# STM32WB10_CM4 register map
File version: 1.5
CPU: CM4 r0p1, little endian, MPU, FPU, 4 interrupt priority bits
Registers are 32-bit, read-write, reset 0x0 unless marked. A register's access mark holds for its fields unless they carry their own. Offsets are from the block's base; [hi:lo] are bit positions; {n}, {i} and the like mark numbered series; 'fields as' and 'values as' point back to an identical list.

## DMAMUX — Direct memory access Multiplexer
Base 0x40020800
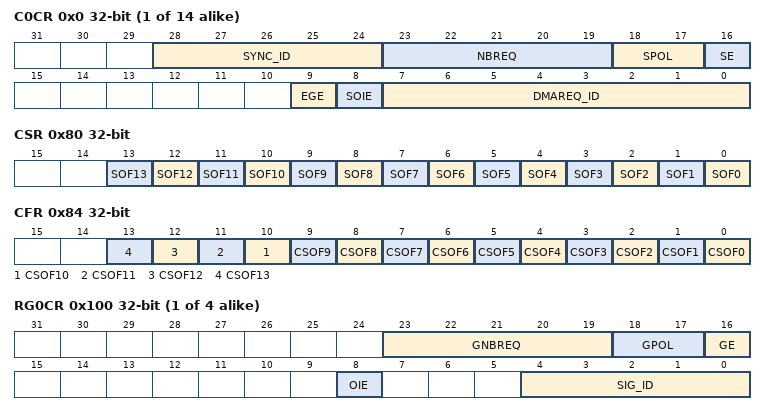
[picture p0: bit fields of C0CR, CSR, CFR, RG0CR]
{0x0+4i} C{i}CR (i=0..13) — DMA Multiplexer Channel {i} Control register
  [28:24] SYNC_ID
  [23:19] NBREQ — Nb request
  [18:17] SPOL — Sync polarity
  [16] SE — Synchronization enable
  [9] EGE — Event Generation Enable
  [8] SOIE — Synchronization Overrun Interrupt Enable
  [7:0] DMAREQ_ID — DMA Request ID
0x80 CSR ro — DMA Multiplexer Channel Status register
  [n] SOF{n} (n=0..13) — Synchronization Overrun Flag {n}
0x84 CFR wo — DMA Channel Clear Flag Register
  [n] CSOF{n} (n=0..13) — Synchronization Clear Overrun Flag {n}
{0x100+4i} RG{i}CR (i=0..3) — DMA Request Generator {i} Control Register
  [23:19] GNBREQ — Number of Request
  [18:17] GPOL — Generation Polarity
  [16] GE — Generation Enable
  [8] OIE — Overrun Interrupt Enable
  [4:0] SIG_ID — Signal ID
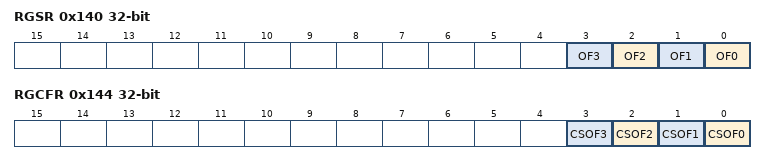
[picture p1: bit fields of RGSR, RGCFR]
0x140 RGSR ro — DMA Request Generator Status Register
  [n] OF{n} (n=0..3) — Generator Overrun Flag {n}
0x144 RGCFR ro — DMA Request Generator Clear Flag Register
  [n] CSOF{n} (n=0..3) — Generator Clear Overrun Flag {n}

## EXTI — External interrupt/event controller
Base 0x58000800
0x00 RTSR1 — rising trigger selection register
  [20:0] RT — Rising trigger event configuration bit of Configurable Event input
0x04 FTSR1 — falling trigger selection register
  [20:0] FT — Falling trigger event configuration bit of Configurable Event input
0x08 SWIER1 — software interrupt event register
  [20:0] SWI — Software interrupt on event
0x0C PR1 — EXTI pending register
  [20:0] PIF — Configurable event inputs Pending bit
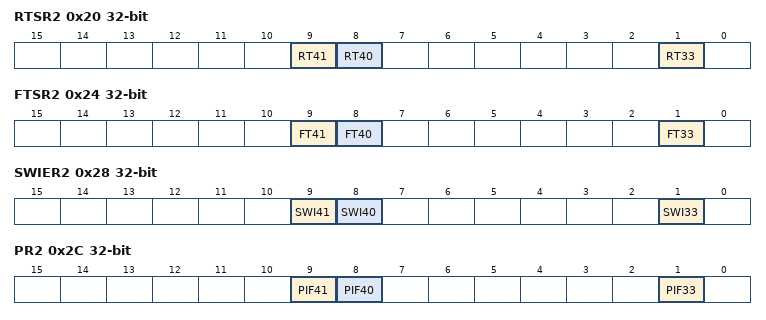
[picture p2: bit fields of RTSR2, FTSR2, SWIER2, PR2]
0x20 RTSR2 — rising trigger selection register
  [9] RT41 — Rising trigger event configuration bit of Configurable Event input 41
  [8] RT40 — Rising trigger event configuration bit of Configurable Event input 40
  [1] RT33 — Rising trigger event configuration bit of Configurable Event input
0x24 FTSR2 — falling trigger selection register
  [9] FT41 — Falling trigger event configuration bit of configurable event input 41
  [8] FT40 — Falling trigger event configuration bit of configurable event input 40
  [1] FT33 — Falling trigger event configuration bit of Configurable Event input
0x28 SWIER2 — software interrupt event register
  [9] SWI41 — Software interrupt on event
  [8] SWI40 — Software interrupt on event
  [1] SWI33 — Software interrupt on event
0x2C PR2 — pending register
  [9] PIF41 — Configurable event inputs x+32 Pending bit.
  [8] PIF40 — Configurable event inputs x+32 Pending bit.
  [1] PIF33 — Configurable event inputs x+32 Pending bit.
0x80 IMR1 reset 0x7FC00000 — CPUm wakeup with interrupt mask register
  [31:0] IM — CPU(m) wakeup with interrupt Mask on Event input
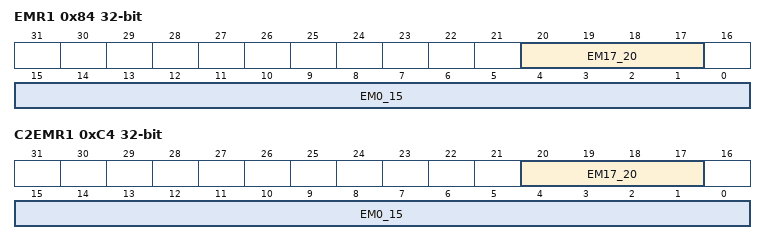
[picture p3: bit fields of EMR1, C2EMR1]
0x84 EMR1 — CPUm wakeup with event mask register
  [20:17] EM17_20 — CPU(m) Wakeup with event generation Mask on Event input
  [15:0] EM0_15 — CPU(m) Wakeup with event generation Mask on Event input
0x90 IMR2 reset 0x1FCFD — CPUm wakeup with interrupt mask register
  [17:1] IM — CPUm Wakeup with interrupt Mask on Event input
0x94 EMR2 — CPUm wakeup with event mask register
  [9:8] EM — CPU(m) Wakeup with event generation Mask on Event input
0xC0 C2IMR1 reset 0x7FC00000 — CPUm wakeup with interrupt mask register
  [31:0] IM — CPU(m) wakeup with interrupt Mask on Event input
0xC4 C2EMR1 — CPUm wakeup with event mask register
  fields as EMR1
0xD0 C2IMR2 reset 0x1FCFD — CPUm wakeup with interrupt mask register
  [17:1] IM — CPUm Wakeup with interrupt Mask on Event input
0xD4 C2EMR2 — CPUm wakeup with event mask register
  [9:8] EM — CPU(m) Wakeup with event generation Mask on Event input

## GPIOA — General-purpose I/Os
Base 0x48000000
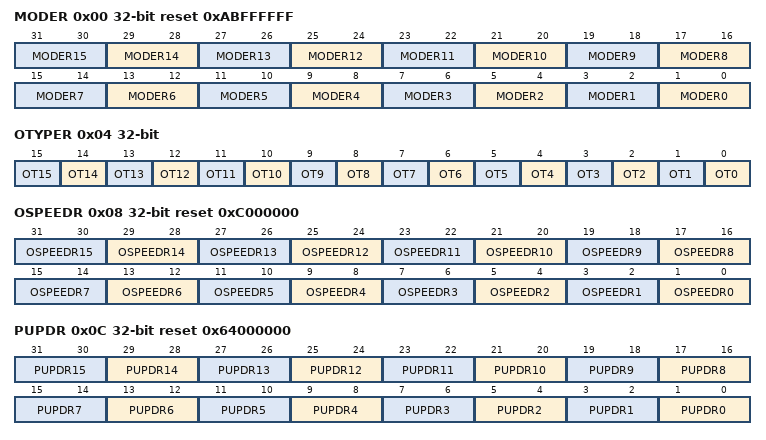
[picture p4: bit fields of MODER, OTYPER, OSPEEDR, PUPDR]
0x00 MODER reset 0xABFFFFFF — GPIO port mode register
  [2n+1:2n] MODER{n} (n=0..15) — Port x configuration bits (y = 0..15)
0x04 OTYPER — GPIO port output type register
  [n] OT{n} (n=0..15) — Port x configuration bits (y = 0..15)
0x08 OSPEEDR reset 0xC000000 — GPIO port output speed register
  [2n+1:2n] OSPEEDR{n} (n=0..15) — Port x configuration bits (y = 0..15)
0x0C PUPDR reset 0x64000000 — GPIO port pull-up/pull-down register
  [2n+1:2n] PUPDR{n} (n=0..15) — Port x configuration bits (y = 0..15)
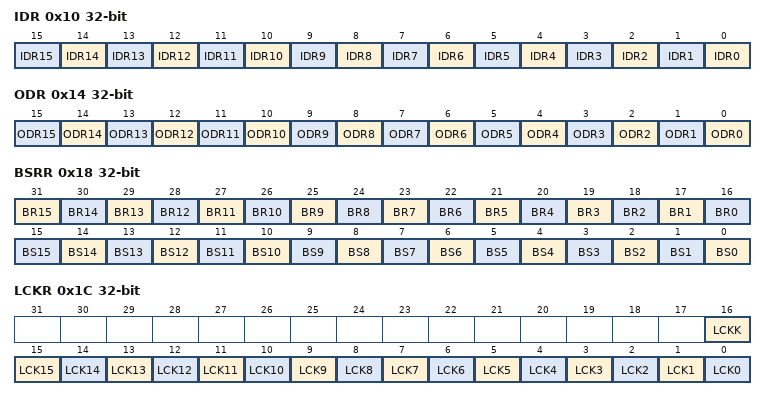
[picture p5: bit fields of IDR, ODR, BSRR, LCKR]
0x10 IDR ro — GPIO port input data register
  [n] IDR{n} (n=0..15) — Port input data (y = 0..15)
0x14 ODR — GPIO port output data register
  [n] ODR{n} (n=0..15) — Port output data (y = 0..15)
0x18 BSRR wo — GPIO port bit set/reset register
  [n+16] BR{n} (n=1..15) — Port x reset bit y (y = 0..15)
  [16] BR0 — Port x set bit y (y= 0..15)
  [n] BS{n} (n=0..15) — Port x set bit y (y= 0..15)
0x1C LCKR — GPIO port configuration lock register
  [16] LCKK — Port x lock bit y (y= 0..15)
  [n] LCK{n} (n=0..15) — Port x lock bit y (y= 0..15)
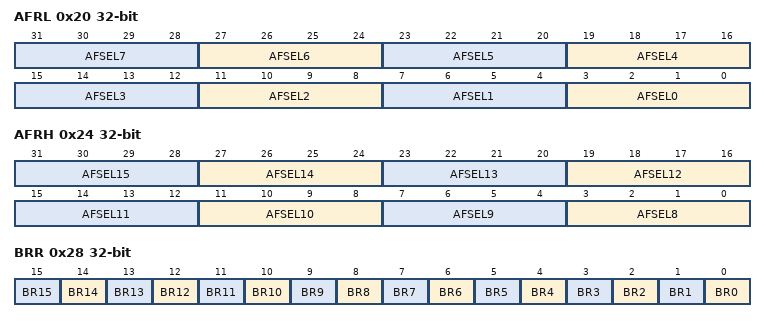
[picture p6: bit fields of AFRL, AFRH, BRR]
0x20 AFRL — GPIO alternate function low register
  [4n+3:4n] AFSEL{n} (n=0..7) — Alternate function selection for port x bit y (y = 0..7)
0x24 AFRH — GPIO alternate function high register
  [4n-29:4n-32] AFSEL{n} (n=8..15) — Alternate function selection for port x bit y (y = 8..15)
0x28 BRR wo — port bit reset register
  [n] BR{n} (n=0..15) — Port Reset bit

## GPIOB — General-purpose I/Os
Base 0x48000400
Registers as GPIOA; these are added or differ:
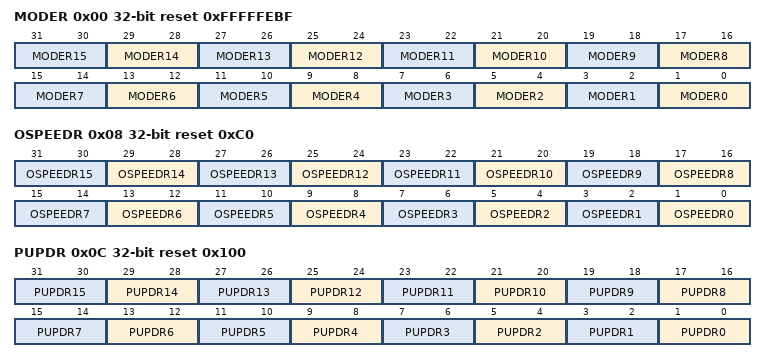
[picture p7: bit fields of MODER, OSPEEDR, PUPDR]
0x00 MODER reset 0xFFFFFEBF — GPIO port mode register
  [2n+1:2n] MODER{n} (n=0..15) — Port x configuration bits (y = 0..15)
0x08 OSPEEDR reset 0xC0 — GPIO port output speed register
  [2n+1:2n] OSPEEDR{n} (n=0..15) — Port x configuration bits (y = 0..15)
0x0C PUPDR reset 0x100 — GPIO port pull-up/pull-down register
  [2n+1:2n] PUPDR{n} (n=0..15) — Port x configuration bits (y = 0..15)

## GPIOC — General-purpose I/Os
Base 0x48000800
Registers as GPIOB; these are added or differ:
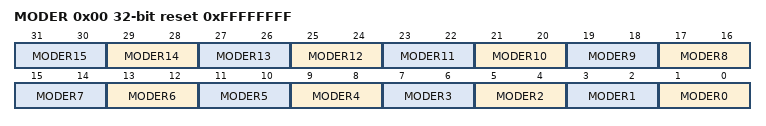
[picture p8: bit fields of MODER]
0x00 MODER reset 0xFFFFFFFF — GPIO port mode register
  [2n+1:2n] MODER{n} (n=0..15) — Port x configuration bits (y = 0..15)

## Notices in the file
Copyright (c) 2024 STMicroelectronics.
SPDX-License-Identifier: Apache-2.0
Licensed under the Apache License, Version 2.0 (the "License");
you may not use this file except in compliance with the License.
You may obtain a copy of the License at
http://www.apache.org/licenses/LICENSE-2.0
Unless required by applicable law or agreed to in writing, software
distributed under the License is distributed on an "AS IS" BASIS,
WITHOUT WARRANTIES OR CONDITIONS OF ANY KIND, either express or implied.
See the License for the specific language governing permissions and
limitations under the License.
